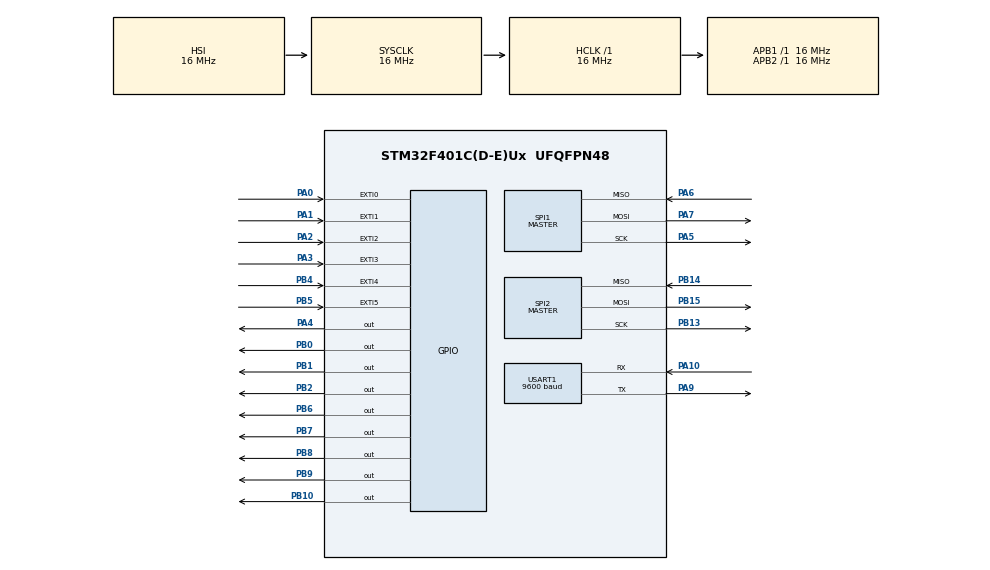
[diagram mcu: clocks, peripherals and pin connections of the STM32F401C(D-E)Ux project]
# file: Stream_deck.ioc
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Mcu.Family=STM32F4
Mcu.Name=STM32F401C(D-E)Ux
Mcu.Package=UFQFPN48
NVIC.EXTI0_IRQn=true\:0\:0\:false\:false\:true\:true\:true\:true
NVIC.EXTI1_IRQn=true\:0\:0\:false\:false\:true\:true\:true\:true
NVIC.EXTI2_IRQn=true\:0\:0\:false\:false\:true\:true\:true\:true
NVIC.EXTI3_IRQn=true\:0\:0\:false\:false\:true\:true\:true\:true
NVIC.EXTI4_IRQn=true\:0\:0\:false\:false\:true\:true\:true\:true
NVIC.EXTI9_5_IRQn=true\:0\:0\:false\:false\:true\:true\:true\:true
NVIC.PriorityGroup=NVIC_PRIORITYGROUP_4
NVIC.TIM3_IRQn=true\:0\:0\:false\:false\:true\:true\:true\:true
PA0-WKUP.GPIO_ModeDefaultEXTI=GPIO_MODE_IT_FALLING
PA0-WKUP.GPIO_PuPd=GPIO_PULLUP
PA0-WKUP.Signal=GPXTI0
PA1.GPIO_ModeDefaultEXTI=GPIO_MODE_IT_FALLING
PA1.GPIO_PuPd=GPIO_PULLUP
PA1.Signal=GPXTI1
PA10.Mode=Asynchronous
PA10.Signal=USART1_RX
PA2.GPIO_ModeDefaultEXTI=GPIO_MODE_IT_FALLING
PA2.GPIO_PuPd=GPIO_PULLUP
PA2.Signal=GPXTI2
PA3.GPIO_ModeDefaultEXTI=GPIO_MODE_IT_FALLING
PA3.GPIO_PuPd=GPIO_PULLUP
PA3.Signal=GPXTI3
PA4.Signal=GPIO_Output
PA5.Mode=Full_Duplex_Master
PA5.Signal=SPI1_SCK
PA6.Mode=Full_Duplex_Master
PA6.Signal=SPI1_MISO
PA7.Mode=Full_Duplex_Master
PA7.Signal=SPI1_MOSI
PA9.Mode=Asynchronous
PA9.Signal=USART1_TX
PB0.Signal=GPIO_Output
PB1.Signal=GPIO_Output
PB10.Signal=GPIO_Output
PB13.Mode=Full_Duplex_Master
PB13.Signal=SPI2_SCK
PB14.Mode=Full_Duplex_Master
PB14.Signal=SPI2_MISO
PB15.Mode=Full_Duplex_Master
PB15.Signal=SPI2_MOSI
PB2.Signal=GPIO_Output
PB4.GPIO_ModeDefaultEXTI=GPIO_MODE_IT_FALLING
PB4.GPIO_PuPd=GPIO_PULLUP
PB4.Signal=GPXTI4
PB5.GPIO_ModeDefaultEXTI=GPIO_MODE_IT_FALLING
PB5.GPIO_PuPd=GPIO_PULLUP
PB5.Signal=GPXTI5
PB6.Signal=GPIO_Output
PB7.Signal=GPIO_Output
PB8.Signal=GPIO_Output
PB9.Signal=GPIO_Output
ProjectManager.HeapSize=0x200
ProjectManager.StackSize=0x400
ProjectManager.TargetToolchain=STM32CubeIDE
RCC.AHBFreq_Value=16000000
RCC.APB1Freq_Value=16000000
RCC.APB2Freq_Value=16000000
RCC.CortexFreq_Value=16000000
RCC.HSE_VALUE=25000000
RCC.HSI_VALUE=16000000
RCC.LSE_VALUE=32768
RCC.SYSCLKFreq_VALUE=16000000
RCC.VCOOutputFreq_Value=192000000
SPI1.BaudRatePrescaler=SPI_BAUDRATEPRESCALER_4
SPI1.Direction=SPI_DIRECTION_2LINES
SPI1.Mode=SPI_MODE_MASTER
SPI1.VirtualType=VM_MASTER
SPI2.BaudRatePrescaler=SPI_BAUDRATEPRESCALER_4
SPI2.Direction=SPI_DIRECTION_2LINES
SPI2.Mode=SPI_MODE_MASTER
SPI2.VirtualType=VM_MASTER
TIM3.Period=50-1
TIM3.Prescaler=16000-1
USART1.BaudRate=9600
USART1.VirtualMode=VM_ASYNC
VP_TIM3_VS_ClockSourceINT.Mode=Internal
board=custom

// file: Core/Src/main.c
/* USER CODE BEGIN Header */
/**
  ******************************************************************************
  * @file           : main.c
  * @brief          : Main program body
  ******************************************************************************
  * @attention
  *
  * Copyright (c) 2026 STMicroelectronics.
  * All rights reserved.
  *
  * This software is licensed under terms that can be found in the LICENSE file
  * in the root directory of this software component.
  * If no LICENSE file comes with this software, it is provided AS-IS.
  *
  ******************************************************************************
  */
/* USER CODE END Header */
#include "main.h"
/* USER CODE BEGIN Includes */
#include "Main_display_control.h"
#include "Button.h"
#include "OLED.h"
/* USER CODE END Includes */

SPI_HandleTypeDef hspi1;
SPI_HandleTypeDef hspi2;

TIM_HandleTypeDef htim3;

UART_HandleTypeDef huart1;

void SystemClock_Config(void);
static void MX_GPIO_Init(void);
static void MX_TIM3_Init(void);
static void MX_USART1_UART_Init(void);
static void MX_SPI2_Init(void);
static void MX_SPI1_Init(void);

int main(void)
{

  /* MCU Configuration--------------------------------------------------------*/

  /* Reset of all peripherals, Initializes the Flash interface and the Systick. */
  HAL_Init();

  /* Configure the system clock */
  SystemClock_Config();

  /* Initialize all configured peripherals */
  MX_GPIO_Init();
  MX_TIM3_Init();
  MX_USART1_UART_Init();
  MX_SPI2_Init();
  MX_SPI1_Init();
  /* USER CODE BEGIN 2 */
  OLED_Init();
  Button_Init();
  State_Trans_Init();
  /* USER CODE END 2 */

  /* Infinite loop */
  while (1)
  {

    /* USER CODE BEGIN 3 */
    Button_State_Reset();
  }
  /* USER CODE END 3 */
}

void SystemClock_Config(void)
{
  RCC_OscInitTypeDef RCC_OscInitStruct = {0};
  RCC_ClkInitTypeDef RCC_ClkInitStruct = {0};

  /** Configure the main internal regulator output voltage
  */
  __HAL_RCC_PWR_CLK_ENABLE();
  __HAL_PWR_VOLTAGESCALING_CONFIG(PWR_REGULATOR_VOLTAGE_SCALE2);

  /** Initializes the RCC Oscillators according to the specified parameters
  * in the RCC_OscInitTypeDef structure.
  */
  RCC_OscInitStruct.OscillatorType = RCC_OSCILLATORTYPE_HSI;
  RCC_OscInitStruct.HSIState = RCC_HSI_ON;
  RCC_OscInitStruct.HSICalibrationValue = RCC_HSICALIBRATION_DEFAULT;
  RCC_OscInitStruct.PLL.PLLState = RCC_PLL_NONE;
  if (HAL_RCC_OscConfig(&RCC_OscInitStruct) != HAL_OK)
  {
    Error_Handler();
  }

  /** Initializes the CPU, AHB and APB buses clocks
  */
  RCC_ClkInitStruct.ClockType = RCC_CLOCKTYPE_HCLK|RCC_CLOCKTYPE_SYSCLK
                              |RCC_CLOCKTYPE_PCLK1|RCC_CLOCKTYPE_PCLK2;
  RCC_ClkInitStruct.SYSCLKSource = RCC_SYSCLKSOURCE_HSI;
  RCC_ClkInitStruct.AHBCLKDivider = RCC_SYSCLK_DIV1;
  RCC_ClkInitStruct.APB1CLKDivider = RCC_HCLK_DIV1;
  RCC_ClkInitStruct.APB2CLKDivider = RCC_HCLK_DIV1;

  if (HAL_RCC_ClockConfig(&RCC_ClkInitStruct, FLASH_LATENCY_0) != HAL_OK)
  {
    Error_Handler();
  }
}

static void MX_SPI1_Init(void)
{

  /* SPI1 parameter configuration*/
  hspi1.Instance = SPI1;
  hspi1.Init.Mode = SPI_MODE_MASTER;
  hspi1.Init.Direction = SPI_DIRECTION_2LINES;
  hspi1.Init.DataSize = SPI_DATASIZE_8BIT;
  hspi1.Init.CLKPolarity = SPI_POLARITY_LOW;
  hspi1.Init.CLKPhase = SPI_PHASE_1EDGE;
  hspi1.Init.NSS = SPI_NSS_SOFT;
  hspi1.Init.BaudRatePrescaler = SPI_BAUDRATEPRESCALER_4;
  hspi1.Init.FirstBit = SPI_FIRSTBIT_MSB;
  hspi1.Init.TIMode = SPI_TIMODE_DISABLE;
  hspi1.Init.CRCCalculation = SPI_CRCCALCULATION_DISABLE;
  hspi1.Init.CRCPolynomial = 10;
  if (HAL_SPI_Init(&hspi1) != HAL_OK)
  {
    Error_Handler();
  }

}

static void MX_SPI2_Init(void)
{

  /* SPI2 parameter configuration*/
  hspi2.Instance = SPI2;
  hspi2.Init.Mode = SPI_MODE_MASTER;
  hspi2.Init.Direction = SPI_DIRECTION_2LINES;
  hspi2.Init.DataSize = SPI_DATASIZE_8BIT;
  hspi2.Init.CLKPolarity = SPI_POLARITY_LOW;
  hspi2.Init.CLKPhase = SPI_PHASE_1EDGE;
  hspi2.Init.NSS = SPI_NSS_SOFT;
  hspi2.Init.BaudRatePrescaler = SPI_BAUDRATEPRESCALER_4;
  hspi2.Init.FirstBit = SPI_FIRSTBIT_MSB;
  hspi2.Init.TIMode = SPI_TIMODE_DISABLE;
  hspi2.Init.CRCCalculation = SPI_CRCCALCULATION_DISABLE;
  hspi2.Init.CRCPolynomial = 10;
  if (HAL_SPI_Init(&hspi2) != HAL_OK)
  {
    Error_Handler();
  }

}

static void MX_TIM3_Init(void)
{

  TIM_ClockConfigTypeDef sClockSourceConfig = {0};
  TIM_MasterConfigTypeDef sMasterConfig = {0};

  htim3.Instance = TIM3;
  htim3.Init.Prescaler = 16000-1;
  htim3.Init.CounterMode = TIM_COUNTERMODE_UP;
  htim3.Init.Period = 50-1;
  htim3.Init.ClockDivision = TIM_CLOCKDIVISION_DIV1;
  htim3.Init.AutoReloadPreload = TIM_AUTORELOAD_PRELOAD_DISABLE;
  if (HAL_TIM_Base_Init(&htim3) != HAL_OK)
  {
    Error_Handler();
  }
  sClockSourceConfig.ClockSource = TIM_CLOCKSOURCE_INTERNAL;
  if (HAL_TIM_ConfigClockSource(&htim3, &sClockSourceConfig) != HAL_OK)
  {
    Error_Handler();
  }
  sMasterConfig.MasterOutputTrigger = TIM_TRGO_RESET;
  sMasterConfig.MasterSlaveMode = TIM_MASTERSLAVEMODE_DISABLE;
  if (HAL_TIMEx_MasterConfigSynchronization(&htim3, &sMasterConfig) != HAL_OK)
  {
    Error_Handler();
  }

}

static void MX_USART1_UART_Init(void)
{

  huart1.Instance = USART1;
  huart1.Init.BaudRate = 9600;
  huart1.Init.WordLength = UART_WORDLENGTH_8B;
  huart1.Init.StopBits = UART_STOPBITS_1;
  huart1.Init.Parity = UART_PARITY_NONE;
  huart1.Init.Mode = UART_MODE_TX_RX;
  huart1.Init.HwFlowCtl = UART_HWCONTROL_NONE;
  huart1.Init.OverSampling = UART_OVERSAMPLING_16;
  if (HAL_UART_Init(&huart1) != HAL_OK)
  {
    Error_Handler();
  }

}

static void MX_GPIO_Init(void)
{
  GPIO_InitTypeDef GPIO_InitStruct = {0};

  /* GPIO Ports Clock Enable */
  __HAL_RCC_GPIOA_CLK_ENABLE();
  __HAL_RCC_GPIOB_CLK_ENABLE();

  /*Configure GPIO pin Output Level */
  HAL_GPIO_WritePin(GPIOA, GPIO_PIN_4, GPIO_PIN_RESET);

  /*Configure GPIO pin Output Level */
  HAL_GPIO_WritePin(GPIOB, GPIO_PIN_0|GPIO_PIN_1|GPIO_PIN_2|GPIO_PIN_10
                          |GPIO_PIN_6|GPIO_PIN_7|GPIO_PIN_8|GPIO_PIN_9, GPIO_PIN_RESET);

  /*Configure GPIO pins : PA0 PA1 PA2 PA3 */
  GPIO_InitStruct.Pin = GPIO_PIN_0|GPIO_PIN_1|GPIO_PIN_2|GPIO_PIN_3;
  GPIO_InitStruct.Mode = GPIO_MODE_IT_FALLING;
  GPIO_InitStruct.Pull = GPIO_PULLUP;
  HAL_GPIO_Init(GPIOA, &GPIO_InitStruct);

  /*Configure GPIO pin : PA4 */
  GPIO_InitStruct.Pin = GPIO_PIN_4;
  GPIO_InitStruct.Mode = GPIO_MODE_OUTPUT_PP;
  GPIO_InitStruct.Pull = GPIO_NOPULL;
  GPIO_InitStruct.Speed = GPIO_SPEED_FREQ_LOW;
  HAL_GPIO_Init(GPIOA, &GPIO_InitStruct);

  /*Configure GPIO pins : PB0 PB1 PB2 PB10
                           PB6 PB7 PB8 PB9 */
  GPIO_InitStruct.Pin = GPIO_PIN_0|GPIO_PIN_1|GPIO_PIN_2|GPIO_PIN_10
                          |GPIO_PIN_6|GPIO_PIN_7|GPIO_PIN_8|GPIO_PIN_9;
  GPIO_InitStruct.Mode = GPIO_MODE_OUTPUT_PP;
  GPIO_InitStruct.Pull = GPIO_NOPULL;
  GPIO_InitStruct.Speed = GPIO_SPEED_FREQ_LOW;
  HAL_GPIO_Init(GPIOB, &GPIO_InitStruct);

  /*Configure GPIO pins : PB4 PB5 */
  GPIO_InitStruct.Pin = GPIO_PIN_4|GPIO_PIN_5;
  GPIO_InitStruct.Mode = GPIO_MODE_IT_FALLING;
  GPIO_InitStruct.Pull = GPIO_PULLUP;
  HAL_GPIO_Init(GPIOB, &GPIO_InitStruct);

  /* EXTI interrupt init*/
  HAL_NVIC_SetPriority(EXTI0_IRQn, 0, 0);
  HAL_NVIC_EnableIRQ(EXTI0_IRQn);

  HAL_NVIC_SetPriority(EXTI1_IRQn, 0, 0);
  HAL_NVIC_EnableIRQ(EXTI1_IRQn);

  HAL_NVIC_SetPriority(EXTI2_IRQn, 0, 0);
  HAL_NVIC_EnableIRQ(EXTI2_IRQn);

  HAL_NVIC_SetPriority(EXTI3_IRQn, 0, 0);
  HAL_NVIC_EnableIRQ(EXTI3_IRQn);

  HAL_NVIC_SetPriority(EXTI4_IRQn, 0, 0);
  HAL_NVIC_EnableIRQ(EXTI4_IRQn);

  HAL_NVIC_SetPriority(EXTI9_5_IRQn, 0, 0);
  HAL_NVIC_EnableIRQ(EXTI9_5_IRQn);

}

void Error_Handler(void)
{
  __disable_irq();
  while (1)
  {
  }
}
